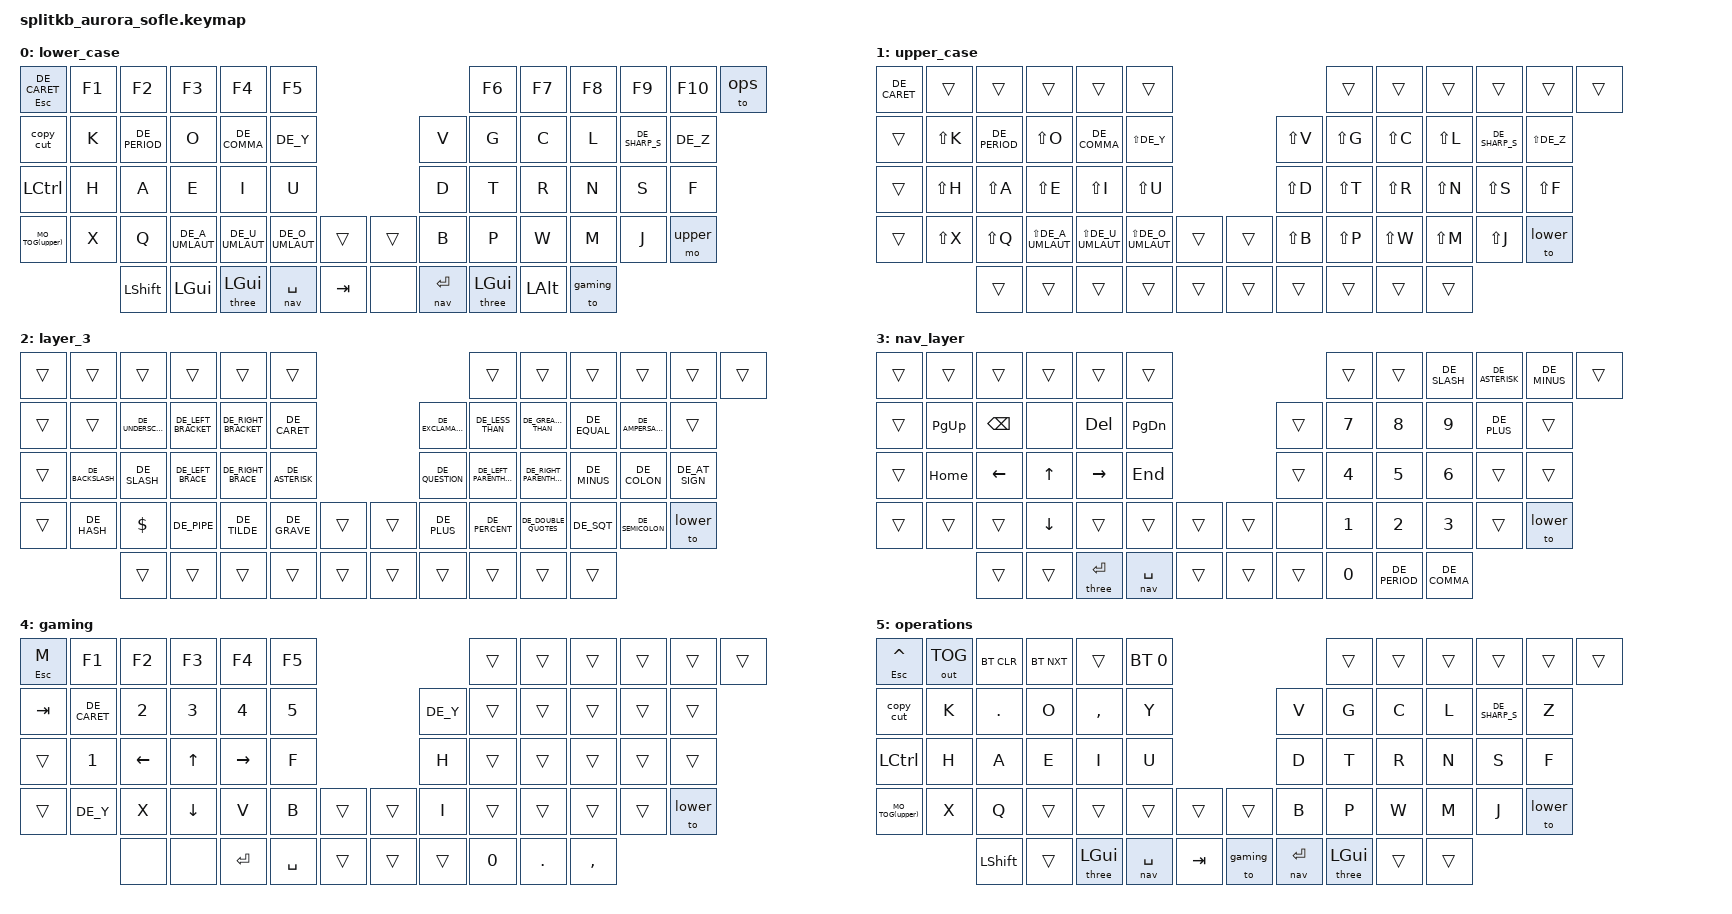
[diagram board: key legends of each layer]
/*
 * Copyright (c) 2023 The ZMK Contributors
 *
 * SPDX-License-Identifier: MIT
 */

#include <behaviors.dtsi>
#include <dt-bindings/zmk/bt.h>
#include <dt-bindings/zmk/outputs.h>
#include <dt-bindings/zmk/ext_power.h>
#include <dt-bindings/zmk/keys.h>

#define HOST_OS 1
#include "zmk-helpers/helper.h"

#include "keys_de.h"

#define lower 0
#define upper 1
#define three 2
#define nav 3
#define gaming 4
#define ops 5

#define MO_TOG(layer) &mo_tog layer layer   // Macro to apply momentary-layer-on-hold/toggle-layer-on-tap to a specific layer


&led_strip {
//    chain-length = <35>;
    chain-length = <6>;
};

/ {
    behaviors {
           copy_cut: td_copy_cut {
               compatible = "zmk,behavior-tap-dance";
               #binding-cells = <0>;
               tapping-term-ms = <200>;
               bindings = <&kp LC(C)>, <&kp LC(V)>, <&kp LC(X)>;
           };
           
           mo_tog: behavior_mo_tog { // momentary-layer-on-hold/toggle-layer-on-tap
                       compatible = "zmk,behavior-hold-tap";
                       #binding-cells = <2>;
                       flavor = "hold-preferred";
                       tapping-term-ms = <200>;
                       bindings = <&mo>, <&tog>;
                   };
                      
           hm: homerow_mods {
               compatible = "zmk,behavior-hold-tap";
               #binding-cells = <2>;
               tapping-term-ms = <150>;
               quick-tap-ms = <0>;
               flavor = "tap-preferred";
               bindings = <&kp>, <&kp>;
           };
       };

    keymap {
        compatible = "zmk,keymap";

        lower_case {
            bindings = <
&hm ESCAPE DE_CARET  &kp F1        &kp F2        &kp F3      &kp F4          &kp F5                                   &kp F6  &kp F7  &kp F8  &kp F9  &kp F10     &to ops
&copy_cut         &kp K         &kp DE_PERIOD    &kp O       &kp DE_COMMA       &kp DE_Y                                    &kp V   &kp G   &kp C   &kp L   &kp DE_SHARP_S  &kp DE_Z
&kp LCTRL         &kp H         &kp A         &kp E       &kp I           &kp U                                    &kp D   &kp T   &kp R   &kp N   &kp S       &kp F
MO_TOG(upper)     &kp X         &kp Q         &kp DE_A_UMLAUT      &kp DE_U_UMLAUT          &kp DE_O_UMLAUT         &trans        &trans      &kp B   &kp P   &kp W   &kp M   &kp J       &mo upper
                                &kp LSHIFT    &kp LGUI    &lt three LGUI  &lt nav SPACE  &kp TAB       &none       &lt nav ENTER  &lt three  LGUI  &kp LALT  &to gaming
            >;
        };

        upper_case {
            bindings = <
&kp DE_CARET  &trans      &trans          &trans      &trans       &trans                           &trans      &trans      &trans      &trans      &trans      &trans
&trans     &kp LS(K)   &kp DE_PERIOD      &kp LS(O)   &kp DE_COMMA    &kp LS(DE_Y)                        &kp LS(V)   &kp LS(G)   &kp LS(C)   &kp LS(L)   &kp DE_SHARP_S  &kp LS(DE_Z)
&trans     &kp LS(H)   &kp LS(A)       &kp LS(E)   &kp LS(I)    &kp LS(U)                        &kp LS(D)   &kp LS(T)   &kp LS(R)   &kp LS(N)   &kp LS(S)     &kp LS(F)
&trans     &kp LS(X)   &kp LS(Q)       &kp LS(DE_A_UMLAUT)      &kp LS(DE_U_UMLAUT)       &kp LS(DE_O_UMLAUT)      &trans    &trans     &kp LS(B)   &kp LS(P)   &kp LS(W)   &kp LS(M)   &kp LS(J)   &to lower
                       &trans          &trans      &trans       &trans      &trans    &trans     &trans      &trans      &trans      &trans
            >;
        };
 
        layer_3 {
            bindings = <
&trans  &trans         &trans          &trans             &trans             &trans                                 &trans           &trans                &trans                 &trans     &trans         &trans
&trans  &trans         &kp DE_UNDERSCORE  &kp DE_LEFT_BRACKET   &kp DE_RIGHT_BRACKET  &kp DE_CARET                              &kp DE_EXCLAMATION  &kp DE_LESS_THAN         &kp DE_GREATER_THAN       &kp DE_EQUAL  &kp DE_AMPERSAND  &trans
&trans  &kp DE_BACKSLASH  &kp DE_SLASH       &kp DE_LEFT_BRACE     &kp DE_RIGHT_BRACE    &kp DE_ASTERISK                           &kp DE_QUESTION     &kp DE_LEFT_PARENTHESIS  &kp DE_RIGHT_PARENTHESIS  &kp DE_MINUS  &kp DE_COLON      &kp DE_AT_SIGN
&trans  &kp DE_HASH       &kp DOLLAR      &kp DE_PIPE           &kp DE_TILDE          &kp DE_GRAVE      &trans    &trans    &kp DE_PLUS         &kp DE_PERCENT           &kp DE_DOUBLE_QUOTES      &kp DE_SQT    &kp DE_SEMICOLON  &to lower
                       &trans          &trans             &trans             &trans         &trans    &trans    &trans           &trans                &trans                 &trans
            >;
        };

        nav_layer {
            bindings = <
&trans  &trans       &trans         &trans           &trans          &trans                             &trans  &trans  &kp DE_SLASH   &kp DE_ASTERISK  &kp DE_MINUS  &trans
&trans  &kp PAGE_UP  &kp BACKSPACE  &none            &kp DELETE      &kp PAGE_DOWN                      &trans  &kp N7  &kp N8      &kp N9        &kp DE_PLUS   &trans
&trans  &kp HOME     &kp LEFT       &kp UP_ARROW     &kp RIGHT       &kp END                            &trans  &kp N4  &kp N5      &kp N6        &trans     &trans
&trans  &trans       &trans         &kp DOWN_ARROW   &trans          &trans           &trans    &trans  &none   &kp N1  &kp N2      &kp N3        &trans     &to lower
                     &trans         &trans           &lt three ENTER &lt nav SPACE    &trans    &trans  &trans  &kp N0  &kp DE_PERIOD  &kp DE_COMMA
            >;
        };

        gaming {
            bindings = <
&hm ESC M    &kp F1     &kp F2    &kp F3    &kp F4        &kp F5                           &trans  &trans  &trans      &trans  &trans   &trans
&kp TAB  &kp DE_CARET  &kp N2    &kp N3    &kp N4        &kp N5                           &kp DE_Y   &trans  &trans      &trans  &trans   &trans
&trans   &kp N1     &kp LEFT  &kp UP    &kp RIGHT     &kp F                            &kp H   &trans  &trans      &trans  &trans   &trans
&trans   &kp DE_Y      &kp X     &kp DOWN  &kp V         &kp B          &trans    &trans  &kp I   &trans  &trans      &trans  &trans   &to lower
                    &none     &none     &kp ENTER     &kp SPACE      &trans    &trans  &trans  &kp N0  &kp PERIOD  &kp COMMA
            >;
        };
        
                operations {
                    bindings = <
        &hm ESCAPE CARET  &out OUT_TOG  &bt BT_CLR    &bt BT_NXT  &trans        &bt BT_SEL 0                             &trans  &trans  &trans  &trans  &trans      &trans
        &copy_cut         &kp K         &kp PERIOD    &kp O       &kp COMMA       &kp Y                                    &kp V   &kp G   &kp C   &kp L   &kp DE_SHARP_S  &kp Z
        &kp LCTRL         &kp H         &kp A         &kp E       &kp I           &kp U                                    &kp D   &kp T   &kp R   &kp N   &kp S       &kp F
        MO_TOG(upper)     &kp X         &kp Q         &trans      &trans          &trans         &trans        &trans      &kp B   &kp P   &kp W   &kp M   &kp J       &to lower
                                        &kp LSHIFT    &trans      &lt three LGUI &lt nav SPACE  &kp TAB          &to gaming  &lt nav ENTER  &lt three  LGUI  &trans  &trans
                    >;
                };
    };
};
